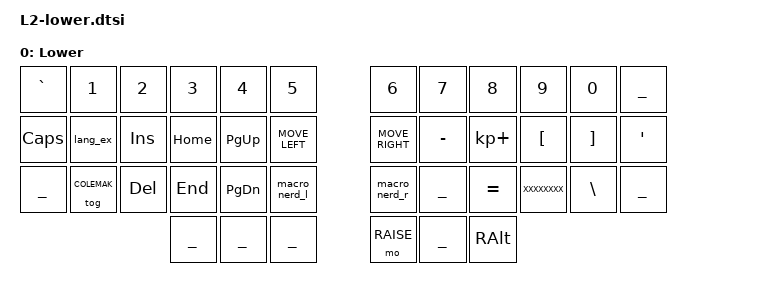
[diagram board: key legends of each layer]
/**
 *
 */

/ {
  keymap {
    compatible = "zmk,keymap";

	lower_layer {
		label = "Lower";
		bindings = <
// ╭───────────────┬───────────────┬───────────────┬───────────────┬───────────────┬───────────────╮   ╭───────────────┬───────────────┬───────────────┬───────────────┬───────────────┬───────────────╮
//  0               1               2               3               4               5                   6               7               8               9               10              11
    &kp GRAVE     	&kp N1          &kp N2          &kp N3          &kp N4          &kp N5              &kp N6          &kp N7          &kp N8          &kp N9          &kp N0          ________
// ├───────────────├───────────────┼───────────────┼───────────────┼───────────────┼───────────────┤   ├───────────────├───────────────┼───────────────┼───────────────┼───────────────┼───────────────┤
//  12              13              14              15              16              17                  18              19              20              21              22              23
	&kp CAPS        &lang_ex    	&kp INS       	&kp HOME        &kp PG_UP       MOVE_LEFT        	MOVE_RIGHT      &kp MINUS     	&kp KP_PLUS		&kp LBKT       	&kp RBKT        &kp SQT
// ├───────────────├───────────────┼───────────────┼───────────────┼───────────────┼───────────────┤   ├───────────────├───────────────┼───────────────┼───────────────┼───────────────┼───────────────┤
//  24              25              26              27              28              29                  30              31              32              33              34              35
    ________      	&tog COLEMAK    &kp DEL        	&kp END        	&kp PG_DN       &macro_nerd_l		&macro_nerd_r   &kp UNDER  		&kp EQUAL       XXXXXXXX        &kp BSLH        ________
// ╰───────────────┴───────────────┴───────────────┼───────────────┼───────────────┼───────────────┤   ├───────────────├───────────────┼───────────────┼───────────────┴───────────────┴───────────────╯
//                                                  36              37              38                  39              40              41
                                    	            ________       	________        ________           	&mo RAISE		________		&kp	RALT
//                                                 ╰───────────────┴───────────────┴───────────────╯   ╰───────────────┴───────────────┴───────────────
			>;
		};
  };
};
